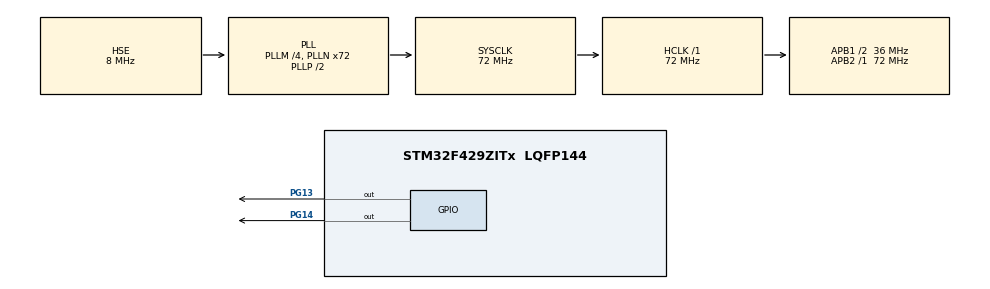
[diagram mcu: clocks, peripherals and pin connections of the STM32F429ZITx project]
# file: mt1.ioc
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Mcu.Family=STM32F4
Mcu.Name=STM32F429ZITx
Mcu.Package=LQFP144
NVIC.PriorityGroup=NVIC_PRIORITYGROUP_4
PC14/OSC32_IN.Mode=LSE-External-Oscillator
PC14/OSC32_IN.Signal=RCC_OSC32_IN
PC15/OSC32_OUT.Mode=LSE-External-Oscillator
PC15/OSC32_OUT.Signal=RCC_OSC32_OUT
PG13.Signal=GPIO_Output
PG14.Signal=GPIO_Output
PH0/OSC_IN.Mode=HSE-External-Oscillator
PH0/OSC_IN.Signal=RCC_OSC_IN
PH1/OSC_OUT.Mode=HSE-External-Oscillator
PH1/OSC_OUT.Signal=RCC_OSC_OUT
ProjectManager.HeapSize=0x200
ProjectManager.StackSize=0x400
ProjectManager.TargetToolchain=STM32CubeIDE
RCC.48MHZClocksFreq_Value=48000000
RCC.AHBFreq_Value=72000000
RCC.APB1CLKDivider=RCC_HCLK_DIV2
RCC.APB1Freq_Value=36000000
RCC.APB1TimFreq_Value=72000000
RCC.APB2Freq_Value=72000000
RCC.APB2TimFreq_Value=72000000
RCC.CortexFreq_Value=72000000
RCC.HCLKFreq_Value=72000000
RCC.HSE_VALUE=8000000
RCC.HSI_VALUE=16000000
RCC.PLLM=4
RCC.PLLN=72
RCC.PLLQ=3
RCC.PLLSAIN=50
RCC.PLLSourceVirtual=RCC_PLLSOURCE_HSE
RCC.SYSCLKFreq_VALUE=72000000
RCC.SYSCLKSource=RCC_SYSCLKSOURCE_PLLCLK
RCC.VCOOutputFreq_Value=144000000
VP_TIM7_VS_ClockSourceINT.Mode=Enable_Timer
board=STM32F429I-DISC1

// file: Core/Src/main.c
/* USER CODE BEGIN Header */
/**
  ******************************************************************************
  * @file           : main.c
  * @brief          : Main program body
  ******************************************************************************
  * @attention
  *
  * Copyright (c) 2023 STMicroelectronics.
  * All rights reserved.
  *
  * This software is licensed under terms that can be found in the LICENSE file
  * in the root directory of this software component.
  * If no LICENSE file comes with this software, it is provided AS-IS.
  *
  ******************************************************************************
  */

//Serdar kaya asci
//Serdar ="S": 83 "E": 69 "R": 82 "D": 68 "A": 65
//kaya= "K": 75 "A": 65 "Y": 89 "A": 65
//Serdar asci sum= 83+69+82+68+65+82=452
//Kaya asci=75+65+89+65=294
//Asci total = 746
//Timernumber=7
//Arrnumber=65535
//Duration=8820
//Ledpinnumber=14

/* USER CODE END Header */
#include "main.h"

/* USER CODE BEGIN PD */
#define TIM_NUMBER 7

#define ARR_NUMBER 65535
#define DURATION 8820
#define LED_PIN_NUMBER 14
#define LED_PORT GPIOG
#define LED_PIN GPIO_PIN_14

/* USER CODE END PD */

TIM_HandleTypeDef htim7;

void SystemClock_Config(void);
static void MX_GPIO_Init(void);
static void MX_TIM7_Init(void);

/* USER CODE BEGIN 0 */
void timerConfig() {

 RCC->APB1ENR |= RCC_APB1ENR_TIM7EN;

TIM7->PSC = 16000 - 1;

TIM7->ARR = ARR_NUMBER;

TIM7->DIER |= TIM_DIER_UIE;

 TIM7->CR1 |= TIM_CR1_CEN;

}

void TIM7_IRQHandler() {

  TIM7->SR &= ~TIM_SR_UIF;
 TIM7->CNT = 1;
 LED_PORT->ODR ^= LED_PIN;
}

/* USER CODE END 0 */

int main(void)
{
  /* USER CODE BEGIN 1 */
	RCC->AHB1ENR |= RCC_AHB1ENR_GPIOGEN;
	  GPIOG->MODER |= (1 << (LED_PIN_NUMBER * 2));

  /* USER CODE END 1 */

  /* MCU Configuration--------------------------------------------------------*/

  /* Reset of all peripherals, Initializes the Flash interface and the Systick. */
  HAL_Init();

  /* Configure the system clock */
  SystemClock_Config();

  /* Initialize all configured peripherals */
  MX_GPIO_Init();
  MX_TIM7_Init();

  /* Infinite loop */
  while (1)
  {
	  if (TIM7->CNT >= DURATION) {

	        TIM7->CNT = 1;

	          LED_PORT->ODR ^= LED_PIN;

	        TIM7->CR1 |= TIM_CR1_CEN;
	  }

  }
}

void SystemClock_Config(void)
{
  RCC_OscInitTypeDef RCC_OscInitStruct = {0};
  RCC_ClkInitTypeDef RCC_ClkInitStruct = {0};

  /** Configure the main internal regulator output voltage
  */
  __HAL_RCC_PWR_CLK_ENABLE();
  __HAL_PWR_VOLTAGESCALING_CONFIG(PWR_REGULATOR_VOLTAGE_SCALE3);

  /** Initializes the RCC Oscillators according to the specified parameters
  * in the RCC_OscInitTypeDef structure.
  */
  RCC_OscInitStruct.OscillatorType = RCC_OSCILLATORTYPE_HSE;
  RCC_OscInitStruct.HSEState = RCC_HSE_ON;
  RCC_OscInitStruct.PLL.PLLState = RCC_PLL_ON;
  RCC_OscInitStruct.PLL.PLLSource = RCC_PLLSOURCE_HSE;
  RCC_OscInitStruct.PLL.PLLM = 4;
  RCC_OscInitStruct.PLL.PLLN = 72;
  RCC_OscInitStruct.PLL.PLLP = RCC_PLLP_DIV2;
  RCC_OscInitStruct.PLL.PLLQ = 3;
  if (HAL_RCC_OscConfig(&RCC_OscInitStruct) != HAL_OK)
  {
    Error_Handler();
  }

  /** Initializes the CPU, AHB and APB buses clocks
  */
  RCC_ClkInitStruct.ClockType = RCC_CLOCKTYPE_HCLK|RCC_CLOCKTYPE_SYSCLK
                              |RCC_CLOCKTYPE_PCLK1|RCC_CLOCKTYPE_PCLK2;
  RCC_ClkInitStruct.SYSCLKSource = RCC_SYSCLKSOURCE_PLLCLK;
  RCC_ClkInitStruct.AHBCLKDivider = RCC_SYSCLK_DIV1;
  RCC_ClkInitStruct.APB1CLKDivider = RCC_HCLK_DIV2;
  RCC_ClkInitStruct.APB2CLKDivider = RCC_HCLK_DIV1;

  if (HAL_RCC_ClockConfig(&RCC_ClkInitStruct, FLASH_LATENCY_2) != HAL_OK)
  {
    Error_Handler();
  }
}

static void MX_TIM7_Init(void)
{

  TIM_MasterConfigTypeDef sMasterConfig = {0};

  htim7.Instance = TIM7;
  htim7.Init.Prescaler = 0;
  htim7.Init.CounterMode = TIM_COUNTERMODE_UP;
  htim7.Init.Period = 65535;
  htim7.Init.AutoReloadPreload = TIM_AUTORELOAD_PRELOAD_DISABLE;
  if (HAL_TIM_Base_Init(&htim7) != HAL_OK)
  {
    Error_Handler();
  }
  sMasterConfig.MasterOutputTrigger = TIM_TRGO_RESET;
  sMasterConfig.MasterSlaveMode = TIM_MASTERSLAVEMODE_DISABLE;
  if (HAL_TIMEx_MasterConfigSynchronization(&htim7, &sMasterConfig) != HAL_OK)
  {
    Error_Handler();
  }

}

static void MX_GPIO_Init(void)
{
  GPIO_InitTypeDef GPIO_InitStruct = {0};

  /* GPIO Ports Clock Enable */
  __HAL_RCC_GPIOC_CLK_ENABLE();
  __HAL_RCC_GPIOH_CLK_ENABLE();
  __HAL_RCC_GPIOG_CLK_ENABLE();

  /*Configure GPIO pin Output Level */
  HAL_GPIO_WritePin(GPIOG, GPIO_PIN_13|GPIO_PIN_14, GPIO_PIN_RESET);

  /*Configure GPIO pins : PG13 PG14 */
  GPIO_InitStruct.Pin = GPIO_PIN_13|GPIO_PIN_14;
  GPIO_InitStruct.Mode = GPIO_MODE_OUTPUT_PP;
  GPIO_InitStruct.Pull = GPIO_NOPULL;
  GPIO_InitStruct.Speed = GPIO_SPEED_FREQ_LOW;
  HAL_GPIO_Init(GPIOG, &GPIO_InitStruct);

}

void Error_Handler(void)
{
  __disable_irq();
  while (1)
  {
  }
}
